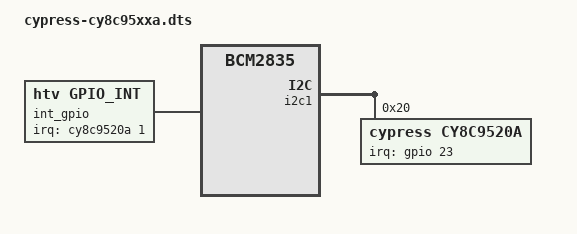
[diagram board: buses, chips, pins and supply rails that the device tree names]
/* Device tree overlay for the cypress cy8c95xxa family of gpio expanders */
/dts-v1/;
/plugin/;

/ {
  compatible = "brcm,bcm2835";

  fragment@0 {
    target = <&i2c1>;

    __overlay__ {
      status = "okay";

      cy8c9520a: ioexp@20 {
        compatible = "cypress,cy8c9520a";
        reg = <0x20>;

        gpio-controller;
        #gpio-cells = <2>;

        interrupt-controller;
        #interrupt-cells = <2>;

        interrupt-parent = <&gpio>;
        /* Could also be 4: active high */
        interrupts = <23 1>;

        gpio-line-names = "GPIO_P0_0",
                          "GPIO_P0_1",
                          "GPIO_P0_2",
                          "GPIO_P0_3",
                          "GPIO_P0_4",
                          "GPIO_P0_5",
                          "GPIO_P0_6",
                          "GPIO_P0_7",
                          "GPIO_P1_0",
                          "GPIO_P1_1",
                          "GPIO_P1_2",
                          "GPIO_P1_3",
                          "GPIO_P1_4",
                          "GPIO_P1_5",
                          "GPIO_P1_6",
                          "GPIO_P1_7",
                          "GPIO_P2_0",
                          "GPIO_P2_1",
                          "GPIO_P2_2",
                          "GPIO_P2_3";

        pinctrl-names = "default";
        pinctrl-0 = <&test_pins>;

        test_pins: pinctrl-test {
          gpio-test {
            pins = "gpio6", "gpio7";
            drive-open-drain;
          };
        };
      };
    };
  };

  fragment@1 {
    target = <&soc>;

    __overlay__ {
        int_gpio {
            compatible = "htv,gpio_int";
            interrupt-parent = <&cy8c9520a>;
            interrupts = <1 3>;
        };
    };
  };
};
